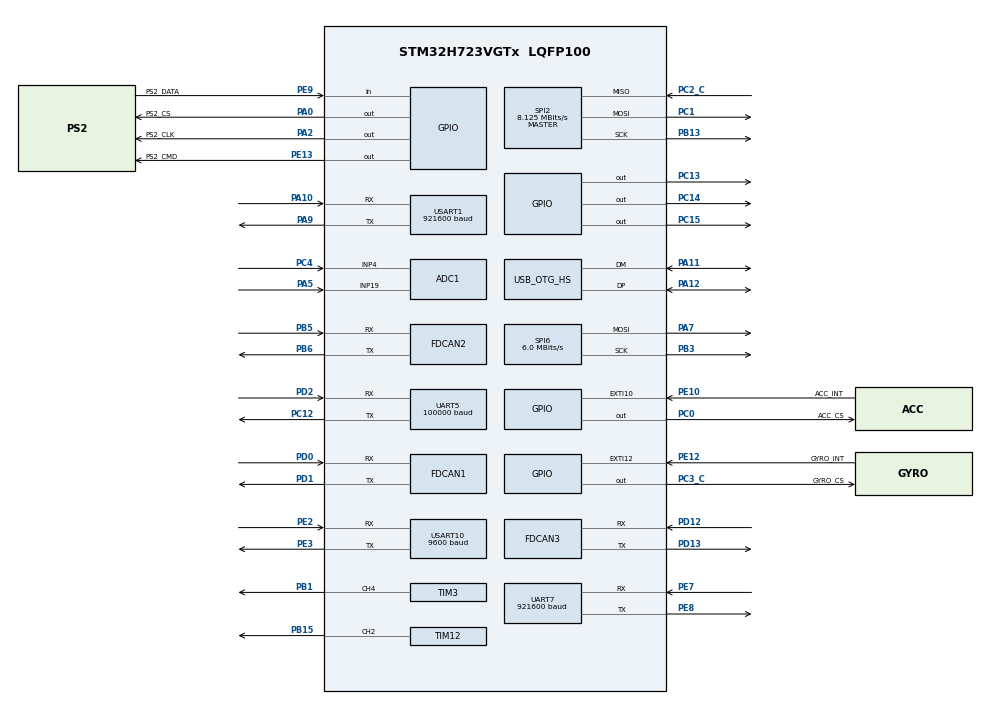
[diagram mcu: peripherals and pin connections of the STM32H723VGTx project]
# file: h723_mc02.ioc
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ADC1.Channel-0\#ChannelRegularConversion=ADC_CHANNEL_4
ADC1.NbrOfConversionFlag=1
ADC1.OffsetNumber-0\#ChannelRegularConversion=ADC_OFFSET_NONE
ADC1.OffsetSignedSaturation-0\#ChannelRegularConversion=DISABLE
ADC1.Rank-0\#ChannelRegularConversion=1
ADC1.SamplingTime-0\#ChannelRegularConversion=ADC_SAMPLETIME_1CYCLE_5
ADC1.master=1
CORTEX_M7.AccessPermission_Spec=MPU_REGION_FULL_ACCESS
CORTEX_M7.BaseAddress_Spec=0x24000000
CORTEX_M7.CPU_DCache=Enabled
CORTEX_M7.CPU_ICache=Enabled
CORTEX_M7.DisableExec_Spec=MPU_INSTRUCTION_ACCESS_ENABLE
CORTEX_M7.IsShareable_Spec=MPU_ACCESS_SHAREABLE
CORTEX_M7.MPU_Control=__NULL
CORTEX_M7.Size_Spec=MPU_REGION_SIZE_512KB
CORTEX_M7.SubRegionDisable_Spec=0x0
CORTEX_M7.TypeExtField_Spec=MPU_TEX_LEVEL1
CORTEX_M7.default_mode_Activation=0
Dma.Request0=USART1_RX
Dma.Request1=USART1_TX
Dma.Request2=UART7_RX
Dma.Request3=UART7_TX
Dma.Request4=UART5_RX
Dma.Request5=SPI2_RX
Dma.Request6=SPI2_TX
Dma.Request7=USART10_RX
Dma.Request8=TIM6_UP
Dma.SPI2_RX.5.Direction=DMA_PERIPH_TO_MEMORY
Dma.SPI2_RX.5.EventEnable=DISABLE
Dma.SPI2_RX.5.FIFOMode=DMA_FIFOMODE_DISABLE
Dma.SPI2_RX.5.Instance=DMA1_Stream0
Dma.SPI2_RX.5.MemDataAlignment=DMA_MDATAALIGN_BYTE
Dma.SPI2_RX.5.MemInc=DMA_MINC_ENABLE
Dma.SPI2_RX.5.Mode=DMA_NORMAL
Dma.SPI2_RX.5.PeriphDataAlignment=DMA_PDATAALIGN_BYTE
Dma.SPI2_RX.5.PeriphInc=DMA_PINC_DISABLE
Dma.SPI2_RX.5.Polarity=HAL_DMAMUX_REQ_GEN_RISING
Dma.SPI2_RX.5.Priority=DMA_PRIORITY_LOW
Dma.SPI2_RX.5.RequestNumber=1
Dma.SPI2_RX.5.SignalID=NONE
Dma.SPI2_RX.5.SyncEnable=DISABLE
Dma.SPI2_RX.5.SyncPolarity=HAL_DMAMUX_SYNC_NO_EVENT
Dma.SPI2_RX.5.SyncRequestNumber=1
Dma.SPI2_RX.5.SyncSignalID=NONE
Dma.SPI2_TX.6.Direction=DMA_MEMORY_TO_PERIPH
Dma.SPI2_TX.6.EventEnable=DISABLE
Dma.SPI2_TX.6.FIFOMode=DMA_FIFOMODE_DISABLE
Dma.SPI2_TX.6.Instance=DMA1_Stream1
Dma.SPI2_TX.6.MemDataAlignment=DMA_MDATAALIGN_BYTE
Dma.SPI2_TX.6.MemInc=DMA_MINC_ENABLE
Dma.SPI2_TX.6.Mode=DMA_NORMAL
Dma.SPI2_TX.6.PeriphDataAlignment=DMA_PDATAALIGN_BYTE
Dma.SPI2_TX.6.PeriphInc=DMA_PINC_DISABLE
Dma.SPI2_TX.6.Polarity=HAL_DMAMUX_REQ_GEN_RISING
Dma.SPI2_TX.6.Priority=DMA_PRIORITY_LOW
Dma.SPI2_TX.6.RequestNumber=1
Dma.SPI2_TX.6.SignalID=NONE
Dma.SPI2_TX.6.SyncEnable=DISABLE
Dma.SPI2_TX.6.SyncPolarity=HAL_DMAMUX_SYNC_NO_EVENT
Dma.SPI2_TX.6.SyncRequestNumber=1
Dma.SPI2_TX.6.SyncSignalID=NONE
Dma.TIM6_UP.8.Direction=DMA_MEMORY_TO_PERIPH
Dma.TIM6_UP.8.EventEnable=DISABLE
Dma.TIM6_UP.8.FIFOMode=DMA_FIFOMODE_DISABLE
Dma.TIM6_UP.8.Instance=DMA2_Stream6
Dma.TIM6_UP.8.MemDataAlignment=DMA_MDATAALIGN_WORD
Dma.TIM6_UP.8.MemInc=DMA_MINC_DISABLE
Dma.TIM6_UP.8.Mode=DMA_NORMAL
Dma.TIM6_UP.8.PeriphDataAlignment=DMA_PDATAALIGN_WORD
Dma.TIM6_UP.8.PeriphInc=DMA_PINC_DISABLE
Dma.TIM6_UP.8.Polarity=HAL_DMAMUX_REQ_GEN_RISING
Dma.TIM6_UP.8.Priority=DMA_PRIORITY_VERY_HIGH
Dma.TIM6_UP.8.RequestNumber=1
Dma.TIM6_UP.8.SignalID=NONE
Dma.TIM6_UP.8.SyncEnable=DISABLE
Dma.TIM6_UP.8.SyncPolarity=HAL_DMAMUX_SYNC_NO_EVENT
Dma.TIM6_UP.8.SyncRequestNumber=1
Dma.TIM6_UP.8.SyncSignalID=NONE
Dma.UART5_RX.4.Direction=DMA_PERIPH_TO_MEMORY
Dma.UART5_RX.4.EventEnable=DISABLE
Dma.UART5_RX.4.FIFOMode=DMA_FIFOMODE_DISABLE
Dma.UART5_RX.4.Instance=DMA2_Stream3
Dma.UART5_RX.4.MemDataAlignment=DMA_MDATAALIGN_BYTE
Dma.UART5_RX.4.MemInc=DMA_MINC_ENABLE
Dma.UART5_RX.4.Mode=DMA_CIRCULAR
Dma.UART5_RX.4.PeriphDataAlignment=DMA_PDATAALIGN_BYTE
Dma.UART5_RX.4.PeriphInc=DMA_PINC_DISABLE
Dma.UART5_RX.4.Polarity=HAL_DMAMUX_REQ_GEN_RISING
Dma.UART5_RX.4.Priority=DMA_PRIORITY_VERY_HIGH
Dma.UART5_RX.4.RequestNumber=1
Dma.UART5_RX.4.SignalID=NONE
Dma.UART5_RX.4.SyncEnable=DISABLE
Dma.UART5_RX.4.SyncPolarity=HAL_DMAMUX_SYNC_NO_EVENT
Dma.UART5_RX.4.SyncRequestNumber=1
Dma.UART5_RX.4.SyncSignalID=NONE
Dma.UART7_RX.2.Direction=DMA_PERIPH_TO_MEMORY
Dma.UART7_RX.2.EventEnable=DISABLE
Dma.UART7_RX.2.FIFOMode=DMA_FIFOMODE_DISABLE
Dma.UART7_RX.2.Instance=DMA1_Stream2
Dma.UART7_RX.2.MemDataAlignment=DMA_MDATAALIGN_BYTE
Dma.UART7_RX.2.MemInc=DMA_MINC_ENABLE
Dma.UART7_RX.2.Mode=DMA_NORMAL
Dma.UART7_RX.2.PeriphDataAlignment=DMA_PDATAALIGN_BYTE
Dma.UART7_RX.2.PeriphInc=DMA_PINC_DISABLE
Dma.UART7_RX.2.Polarity=HAL_DMAMUX_REQ_GEN_RISING
Dma.UART7_RX.2.Priority=DMA_PRIORITY_VERY_HIGH
Dma.UART7_RX.2.RequestNumber=1
Dma.UART7_RX.2.SignalID=NONE
Dma.UART7_RX.2.SyncEnable=DISABLE
Dma.UART7_RX.2.SyncPolarity=HAL_DMAMUX_SYNC_NO_EVENT
Dma.UART7_RX.2.SyncRequestNumber=1
Dma.UART7_RX.2.SyncSignalID=NONE
Dma.UART7_TX.3.Direction=DMA_MEMORY_TO_PERIPH
Dma.UART7_TX.3.EventEnable=DISABLE
Dma.UART7_TX.3.FIFOMode=DMA_FIFOMODE_DISABLE
Dma.UART7_TX.3.Instance=DMA1_Stream3
Dma.UART7_TX.3.MemDataAlignment=DMA_MDATAALIGN_BYTE
Dma.UART7_TX.3.MemInc=DMA_MINC_ENABLE
Dma.UART7_TX.3.Mode=DMA_NORMAL
Dma.UART7_TX.3.PeriphDataAlignment=DMA_PDATAALIGN_BYTE
Dma.UART7_TX.3.PeriphInc=DMA_PINC_DISABLE
Dma.UART7_TX.3.Polarity=HAL_DMAMUX_REQ_GEN_RISING
Dma.UART7_TX.3.Priority=DMA_PRIORITY_VERY_HIGH
Dma.UART7_TX.3.RequestNumber=1
Dma.UART7_TX.3.SignalID=NONE
Dma.UART7_TX.3.SyncEnable=DISABLE
Dma.UART7_TX.3.SyncPolarity=HAL_DMAMUX_SYNC_NO_EVENT
Dma.UART7_TX.3.SyncRequestNumber=1
Dma.UART7_TX.3.SyncSignalID=NONE
Dma.USART10_RX.7.Direction=DMA_PERIPH_TO_MEMORY
Dma.USART10_RX.7.EventEnable=DISABLE
Dma.USART10_RX.7.FIFOMode=DMA_FIFOMODE_DISABLE
Dma.USART10_RX.7.Instance=DMA1_Stream6
Dma.USART10_RX.7.MemDataAlignment=DMA_MDATAALIGN_BYTE
Dma.USART10_RX.7.MemInc=DMA_MINC_ENABLE
Dma.USART10_RX.7.Mode=DMA_NORMAL
Dma.USART10_RX.7.PeriphDataAlignment=DMA_PDATAALIGN_BYTE
Dma.USART10_RX.7.PeriphInc=DMA_PINC_DISABLE
Dma.USART10_RX.7.Polarity=HAL_DMAMUX_REQ_GEN_RISING
Dma.USART10_RX.7.Priority=DMA_PRIORITY_LOW
Dma.USART10_RX.7.RequestNumber=1
Dma.USART10_RX.7.SignalID=NONE
Dma.USART10_RX.7.SyncEnable=DISABLE
Dma.USART10_RX.7.SyncPolarity=HAL_DMAMUX_SYNC_NO_EVENT
Dma.USART10_RX.7.SyncRequestNumber=1
Dma.USART10_RX.7.SyncSignalID=NONE
Dma.USART1_RX.0.Direction=DMA_PERIPH_TO_MEMORY
Dma.USART1_RX.0.EventEnable=DISABLE
Dma.USART1_RX.0.FIFOMode=DMA_FIFOMODE_DISABLE
Dma.USART1_RX.0.Instance=DMA1_Stream4
Dma.USART1_RX.0.MemDataAlignment=DMA_MDATAALIGN_BYTE
Dma.USART1_RX.0.MemInc=DMA_MINC_ENABLE
Dma.USART1_RX.0.Mode=DMA_CIRCULAR
Dma.USART1_RX.0.PeriphDataAlignment=DMA_PDATAALIGN_BYTE
Dma.USART1_RX.0.PeriphInc=DMA_PINC_DISABLE
Dma.USART1_RX.0.Polarity=HAL_DMAMUX_REQ_GEN_RISING
Dma.USART1_RX.0.Priority=DMA_PRIORITY_VERY_HIGH
Dma.USART1_RX.0.RequestNumber=1
Dma.USART1_RX.0.SignalID=NONE
Dma.USART1_RX.0.SyncEnable=DISABLE
Dma.USART1_RX.0.SyncPolarity=HAL_DMAMUX_SYNC_NO_EVENT
Dma.USART1_RX.0.SyncRequestNumber=1
Dma.USART1_RX.0.SyncSignalID=NONE
Dma.USART1_TX.1.Direction=DMA_MEMORY_TO_PERIPH
Dma.USART1_TX.1.EventEnable=DISABLE
Dma.USART1_TX.1.FIFOMode=DMA_FIFOMODE_DISABLE
Dma.USART1_TX.1.Instance=DMA1_Stream5
Dma.USART1_TX.1.MemDataAlignment=DMA_MDATAALIGN_BYTE
Dma.USART1_TX.1.MemInc=DMA_MINC_ENABLE
Dma.USART1_TX.1.Mode=DMA_NORMAL
Dma.USART1_TX.1.PeriphDataAlignment=DMA_PDATAALIGN_BYTE
Dma.USART1_TX.1.PeriphInc=DMA_PINC_DISABLE
Dma.USART1_TX.1.Polarity=HAL_DMAMUX_REQ_GEN_RISING
Dma.USART1_TX.1.Priority=DMA_PRIORITY_VERY_HIGH
Dma.USART1_TX.1.RequestNumber=1
Dma.USART1_TX.1.SignalID=NONE
Dma.USART1_TX.1.SyncEnable=DISABLE
Dma.USART1_TX.1.SyncPolarity=HAL_DMAMUX_SYNC_NO_EVENT
Dma.USART1_TX.1.SyncRequestNumber=1
Dma.USART1_TX.1.SyncSignalID=NONE
FDCAN1.AutoRetransmission=ENABLE
FDCAN1.CalculateBaudRateNominal=1000000
FDCAN1.CalculateTimeBitNominal=1000
FDCAN1.CalculateTimeQuantumNominal=12.5
FDCAN1.DataPrescaler=1
FDCAN1.DataSyncJumpWidth=2
FDCAN1.DataTimeSeg1=13
FDCAN1.DataTimeSeg2=2
FDCAN1.ExtFiltersNbr=0
FDCAN1.FrameFormat=FDCAN_FRAME_FD_BRS
FDCAN1.NominalPrescaler=1
FDCAN1.NominalSyncJumpWidth=20
FDCAN1.NominalTimeSeg1=59
FDCAN1.NominalTimeSeg2=20
FDCAN1.ProtocolException=ENABLE
FDCAN1.RxBuffersNbr=0
FDCAN1.RxFifo0ElmtsNbr=0
FDCAN1.RxFifo1ElmtsNbr=24
FDCAN1.StdFiltersNbr=4
FDCAN1.TxBuffersNbr=0
FDCAN1.TxEventsNbr=0
FDCAN1.TxFifoQueueElmtsNbr=16
FDCAN2.AutoRetransmission=ENABLE
FDCAN2.CalculateBaudRateNominal=1000000
FDCAN2.CalculateTimeBitNominal=1000
FDCAN2.CalculateTimeQuantumNominal=250.0
FDCAN2.DataPrescaler=20
FDCAN2.DataSyncJumpWidth=1
FDCAN2.DataTimeSeg1=2
FDCAN2.DataTimeSeg2=1
FDCAN2.ExtFiltersNbr=0
FDCAN2.FrameFormat=FDCAN_FRAME_CLASSIC
FDCAN2.MessageRAMOffset=853
FDCAN2.NominalPrescaler=20
FDCAN2.NominalSyncJumpWidth=1
FDCAN2.NominalTimeSeg1=2
FDCAN2.NominalTimeSeg2=1
FDCAN2.ProtocolException=ENABLE
FDCAN2.RxFifo0ElmtsNbr=4
FDCAN2.RxFifo1ElmtsNbr=0
FDCAN2.StdFiltersNbr=1
FDCAN2.TxFifoQueueElmtsNbr=2
FDCAN3.AutoRetransmission=ENABLE
FDCAN3.CalculateBaudRateNominal=1000000
FDCAN3.CalculateTimeBitNominal=1000
FDCAN3.CalculateTimeQuantumNominal=250.0
FDCAN3.DataPrescaler=20
FDCAN3.DataSyncJumpWidth=1
FDCAN3.DataTimeSeg1=2
FDCAN3.DataTimeSeg2=1
FDCAN3.ExtFiltersNbr=0
FDCAN3.FrameFormat=FDCAN_FRAME_CLASSIC
FDCAN3.MessageRAMOffset=1706
FDCAN3.NominalPrescaler=20
FDCAN3.NominalSyncJumpWidth=1
FDCAN3.NominalTimeSeg1=2
FDCAN3.NominalTimeSeg2=1
FDCAN3.ProtocolException=ENABLE
FDCAN3.RxFifo0ElmtsNbr=4
FDCAN3.RxFifo1ElmtsNbr=0
FDCAN3.StdFiltersNbr=1
FDCAN3.TxFifoQueueElmtsNbr=2
Mcu.Family=STM32H7
Mcu.Name=STM32H723VGTx
Mcu.Package=LQFP100
NVIC.DMA1_Stream0_IRQn=true\:0\:0\:false\:false\:true\:false\:false\:true\:true
NVIC.DMA1_Stream1_IRQn=true\:0\:0\:false\:false\:true\:false\:false\:true\:true
NVIC.DMA1_Stream2_IRQn=true\:0\:0\:false\:false\:true\:false\:false\:true\:true
NVIC.DMA1_Stream3_IRQn=true\:0\:0\:false\:false\:true\:false\:false\:true\:true
NVIC.DMA1_Stream4_IRQn=true\:0\:0\:false\:false\:true\:false\:false\:true\:true
NVIC.DMA1_Stream5_IRQn=true\:0\:0\:false\:false\:true\:false\:false\:true\:true
NVIC.DMA1_Stream6_IRQn=true\:0\:0\:false\:false\:true\:true\:false\:true\:true
NVIC.DMA2_Stream3_IRQn=true\:0\:0\:false\:false\:true\:false\:false\:true\:true
NVIC.EXTI15_10_IRQn=true\:0\:0\:false\:false\:true\:false\:true\:true\:true
NVIC.FDCAN1_IT0_IRQn=true\:0\:0\:false\:false\:true\:false\:true\:true\:true
NVIC.FDCAN1_IT1_IRQn=true\:0\:0\:false\:false\:true\:false\:true\:true\:true
NVIC.FDCAN2_IT0_IRQn=true\:0\:0\:false\:false\:true\:false\:true\:true\:true
NVIC.FDCAN2_IT1_IRQn=true\:0\:0\:false\:false\:true\:false\:true\:true\:true
NVIC.FDCAN3_IT0_IRQn=true\:0\:0\:false\:false\:true\:false\:true\:true\:true
NVIC.OTG_HS_IRQn=true\:0\:0\:false\:false\:true\:false\:true\:true\:true
NVIC.PriorityGroup=NVIC_PRIORITYGROUP_4
NVIC.SPI2_IRQn=true\:0\:0\:false\:false\:true\:false\:false\:true\:true
NVIC.TIM23_IRQn=true\:15\:0\:false\:false\:true\:false\:false\:true\:true
NVIC.TimeBase=TIM23_IRQn
NVIC.TimeBaseIP=TIM23
NVIC.UART5_IRQn=true\:0\:0\:false\:false\:true\:false\:true\:true\:true
NVIC.UART7_IRQn=true\:0\:0\:false\:false\:true\:false\:true\:true\:true
NVIC.USART10_IRQn=true\:0\:0\:false\:false\:true\:false\:true\:true\:true
NVIC.USART1_IRQn=true\:0\:0\:false\:false\:true\:false\:true\:true\:true
PA0.GPIO_Label=PS2_CS
PA0.PinState=GPIO_PIN_SET
PA0.Signal=GPIO_Output
PA10.Mode=Asynchronous
PA10.Signal=USART1_RX
PA11.Mode=Device_Only_FS
PA11.Signal=USB_OTG_HS_DM
PA12.Mode=Device_Only_FS
PA12.Signal=USB_OTG_HS_DP
PA2.GPIO_Label=PS2_CLK
PA2.PinState=GPIO_PIN_SET
PA2.Signal=GPIO_Output
PA5.Signal=ADCx_INP19
PA7.Mode=TX_Only_Simplex_Unidirect_Master
PA7.Signal=SPI6_MOSI
PA9.Mode=Asynchronous
PA9.Signal=USART1_TX
PB1.Signal=S_TIM3_CH4
PB13.GPIO_Speed=GPIO_SPEED_FREQ_VERY_HIGH
PB13.Mode=Full_Duplex_Master
PB13.Signal=SPI2_SCK
PB15.Signal=S_TIM12_CH2
PB3(JTDO/TRACESWO).Mode=TX_Only_Simplex_Unidirect_Master
PB3(JTDO/TRACESWO).Signal=SPI6_SCK
PB5.Mode=FDCAN_Activate
PB5.Signal=FDCAN2_RX
PB6.Mode=FDCAN_Activate
PB6.Signal=FDCAN2_TX
PC0.GPIO_Label=ACC_CS
PC0.GPIO_Speed=GPIO_SPEED_FREQ_VERY_HIGH
PC0.PinState=GPIO_PIN_SET
PC0.Signal=GPIO_Output
PC1.GPIO_Speed=GPIO_SPEED_FREQ_VERY_HIGH
PC1.Mode=Full_Duplex_Master
PC1.Signal=SPI2_MOSI
PC12.Mode=Asynchronous
PC12.Signal=UART5_TX
PC13.PinState=GPIO_PIN_SET
PC13.Signal=GPIO_Output
PC14-OSC32_IN.PinState=GPIO_PIN_SET
PC14-OSC32_IN.Signal=GPIO_Output
PC15-OSC32_OUT.PinState=GPIO_PIN_SET
PC15-OSC32_OUT.Signal=GPIO_Output
PC2_C.GPIO_Speed=GPIO_SPEED_FREQ_VERY_HIGH
PC2_C.Mode=Full_Duplex_Master
PC2_C.Signal=SPI2_MISO
PC3_C.GPIO_Label=GYRO_CS
PC3_C.GPIO_Speed=GPIO_SPEED_FREQ_VERY_HIGH
PC3_C.PinState=GPIO_PIN_SET
PC3_C.Signal=GPIO_Output
PC4.Signal=ADCx_INP4
PD0.Mode=FDCAN_Activate
PD0.Signal=FDCAN1_RX
PD1.Mode=FDCAN_Activate
PD1.Signal=FDCAN1_TX
PD12.Mode=FDCAN_Activate
PD12.Signal=FDCAN3_RX
PD13.Mode=FDCAN_Activate
PD13.Signal=FDCAN3_TX
PD2.GPIO_Speed=GPIO_SPEED_FREQ_LOW
PD2.Mode=Asynchronous
PD2.Signal=UART5_RX
PE10.GPIO_Label=ACC_INT
PE10.Signal=GPXTI10
PE12.GPIO_Label=GYRO_INT
PE12.Signal=GPXTI12
PE13.GPIO_Label=PS2_CMD
PE13.PinState=GPIO_PIN_SET
PE13.Signal=GPIO_Output
PE2.Mode=Asynchronous
PE2.Signal=USART10_RX
PE3.Mode=Asynchronous
PE3.Signal=USART10_TX
PE7.Mode=Asynchronous
PE7.Signal=UART7_RX
PE8.Mode=Asynchronous
PE8.Signal=UART7_TX
PE9.GPIO_Label=PS2_DATA
PE9.Signal=GPIO_Input
PH0-OSC_IN.Mode=HSE-External-Oscillator
PH0-OSC_IN.Signal=RCC_OSC_IN
PH1-OSC_OUT.Mode=HSE-External-Oscillator
PH1-OSC_OUT.Signal=RCC_OSC_OUT
ProjectManager.HeapSize=0x4000
ProjectManager.StackSize=0x4500
ProjectManager.TargetToolchain=CMake
RCC.ADCFreq_Value=120000000
RCC.APB1Freq_Value=130000000
RCC.APB2Freq_Value=130000000
RCC.APB3Freq_Value=130000000
RCC.APB4Freq_Value=130000000
RCC.CortexFreq_Value=520000000
RCC.D1PPRE=RCC_APB3_DIV2
RCC.D2PPRE1=RCC_APB1_DIV2
RCC.D2PPRE2=RCC_APB2_DIV2
RCC.D3PPRE=RCC_APB4_DIV2
RCC.DIVM1=3
RCC.DIVM2=2
RCC.DIVM3=2
RCC.DIVN1=65
RCC.DIVN2=20
RCC.DIVN3=16
RCC.DIVP1=1
RCC.DIVP3=1
RCC.DIVQ1=4
RCC.DIVQ2=3
RCC.FDCANCLockSelection=RCC_FDCANCLKSOURCE_PLL2
RCC.HCLKFreq_Value=260000000
RCC.HPRE=RCC_HCLK_DIV2
RCC.HSE_VALUE=24000000
RCC.PLL2FRACN=0
RCC.PLL3FRACN=0
RCC.PLL3_VCI_Range-AdvancedSettings=RCC_PLL3VCIRANGE_3
RCC.PLLFRACN=0
RCC.PLLSourceVirtual=RCC_PLLSOURCE_HSE
RCC.SPI6CLockSelection=RCC_SPI6CLKSOURCE_HSE
RCC.SYSCLKFreq_VALUE=520000000
RCC.SYSCLKSource=RCC_SYSCLKSOURCE_PLLCLK
RCC.USBCLockSelection=RCC_USBCLKSOURCE_HSI48
RCC.USBFreq_Value=48000000
SH.ADCx_INP19.0=ADC1_INP19,IN19-Single-Ended
SH.ADCx_INP4.0=ADC1_INP4,IN4-Single-Ended
SH.S_TIM12_CH2.0=TIM12_CH2,PWM Generation2 CH2
SH.S_TIM3_CH4.0=TIM3_CH4,PWM Generation4 CH4
SPI2.BaudRatePrescaler=SPI_BAUDRATEPRESCALER_16
SPI2.CLKPhase=SPI_PHASE_2EDGE
SPI2.CLKPolarity=SPI_POLARITY_HIGH
SPI2.CalculateBaudRate=8.125 MBits/s
SPI2.DataSize=SPI_DATASIZE_8BIT
SPI2.Direction=SPI_DIRECTION_2LINES
SPI2.Mode=SPI_MODE_MASTER
SPI2.VirtualType=VM_MASTER
SPI6.BaudRatePrescaler=SPI_BAUDRATEPRESCALER_4
SPI6.CLKPhase=SPI_PHASE_2EDGE
SPI6.CalculateBaudRate=6.0 MBits/s
SPI6.DataSize=SPI_DATASIZE_8BIT
SPI6.Direction=SPI_DIRECTION_2LINES_TXONLY
SPI6.Mode=SPI_MODE_MASTER
SPI6.VirtualType=VM_MASTER
STMicroelectronics.X-CUBE-ALGOBUILD.1.4.0.LibraryCcDSPOoLibraryJjDSPOoLibrary=true
STMicroelectronics.X-CUBE-AZRTOS-H7.3.4.0.TX_DISABLE_ERROR_CHECKING=1
STMicroelectronics.X-CUBE-AZRTOS-H7.3.4.0.TX_DISABLE_REDUNDANT_CLEARING=1
STMicroelectronics.X-CUBE-AZRTOS-H7.3.4.0.TX_DISABLE_STACK_FILLING=1
STMicroelectronics.X-CUBE-AZRTOS-H7.3.4.0.TX_INLINE_THREAD_RESUME_SUSPEND=1
STMicroelectronics.X-CUBE-AZRTOS-H7.3.4.0.TX_NOT_INTERRUPTABLE=1
STMicroelectronics.X-CUBE-AZRTOS-H7.3.4.0.TX_REACTIVATE_INLINE=1
STMicroelectronics.X-CUBE-AZRTOS-H7.3.4.0.TX_TIMER_PROCESS_IN_ISR=1
STMicroelectronics.X-CUBE-AZRTOS-H7.3.4.0.TX_TIMER_TICKS_PER_SECOND=1000
STMicroelectronics.X-CUBE-AZRTOS-H7.3.4.0.ThreadXCcRTOSJjThreadXJjCore=true
STMicroelectronics.X-CUBE-AZRTOS-H7.3.4.0.USBD_CDCACM_EPINCMD_ADDR=2
STMicroelectronics.X-CUBE-AZRTOS-H7.3.4.0.USBD_PRODUCT_STRING=Doraemon
STMicroelectronics.X-CUBE-AZRTOS-H7.3.4.0.USBD_SERIAL_NUMBER=LXYPIG
STMicroelectronics.X-CUBE-AZRTOS-H7.3.4.0.USBXCcUSBJjUSBXJjCoreSystem=true
STMicroelectronics.X-CUBE-AZRTOS-H7.3.4.0.USBXCcUSBJjUSBXJjUXOoDeviceOoClassOoCDCOoACM=true
STMicroelectronics.X-CUBE-AZRTOS-H7.3.4.0.USBXCcUSBJjUSBXJjUXOoDeviceOoControllers=true
STMicroelectronics.X-CUBE-AZRTOS-H7.3.4.0.USBXCcUSBJjUSBXJjUXOoDeviceOoCoreStack=true
STMicroelectronics.X-CUBE-AZRTOS-H7.3.4.0.USBX_DEVICE_SYS_SIZE=7*1024
STMicroelectronics.X-CUBE-AZRTOS-H7.3.4.0.UX_DEVICE_APP_MEM_POOL_SIZE=12*1024
STMicroelectronics.X-CUBE-AZRTOS-H7.3.4.0.UX_DEVICE_SIDE_ONLY=1
STMicroelectronics.X-CUBE-AZRTOS-H7.3.4.0.UX_PERIODIC_RATE=1000
STMicroelectronics.X-CUBE-AZRTOS-H7.3.4.0.UX_SLAVE_REQUEST_DATA_MAX_LENGTH=512
STMicroelectronics.X-CUBE-AZRTOS-H7.3.4.0.UX_THREAD_STACK_SIZE=2048
STMicroelectronics.X-CUBE-AZRTOS-H7.3.4.0_IsAnAzureRtosMw=true
TIM12.Channel-PWM\ Generation2\ CH2=TIM_CHANNEL_2
TIM12.Period=2000-1
TIM12.Prescaler=24-1
TIM12.Pulse-PWM\ Generation2\ CH2=1000
TIM3.Channel-PWM\ Generation4\ CH4=TIM_CHANNEL_4
TIM3.Period=2000-1
TIM3.Prescaler=33-1
TIM6.Period=2500-1
TIM6.Prescaler=26000-1
UART5.BaudRate=100000
UART5.Mode=MODE_RX
UART5.StopBits=UART_STOPBITS_2
UART5.WordLength=WORDLENGTH_9B
UART7.BaudRate=921600
USART1.BaudRate=921600
USART1.VirtualMode-Asynchronous=VM_ASYNC
USART10.BaudRate=9600
USART10.VirtualMode=VM_ASYNC
USB_OTG_HS.VirtualMode-Device_Only_FS=Device_Only_FS
VP_CRC_VS_CRC.Mode=CRC_Activate
VP_MEMORYMAP_VS_MEMORYMAP.Mode=CurAppReg
VP_RCC_USB.Mode=USB_HS
VP_STMicroelectronics.X-CUBE-ALGOBUILD_VS_DSPOoLibraryJjLibrary_1.4.0_1.4.0.Mode=DSPOoLibraryJjLibrary
VP_STMicroelectronics.X-CUBE-AZRTOS-H7_VS_RTOSJjThreadX_6.4.0_3.4.0.Mode=RTOSJjThreadX
VP_STMicroelectronics.X-CUBE-AZRTOS-H7_VS_USBJjUSBX_6.4.0_3.4.0.Mode=USBJjUSBX
VP_SYS_VS_tim23.Mode=TIM23
VP_TIM6_VS_ClockSourceINT.Mode=Enable_Timer
VP_TIM6_VS_OPM.Mode=OPM_bit
board=custom
TIM7.Period=65535
TIM7.Prescaler=260-1
VP_TIM7_VS_ClockSourceINT.Mode=Enable_Timer
VP_TIM7_VS_OPM.Mode=OPM_bit
NVIC.TIM7_IRQn=true\:14\:0\:true\:false\:true\:false\:true\:true\:true

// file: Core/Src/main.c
/* USER CODE BEGIN Header */
/**
  ******************************************************************************
  * @file           : main.c
  * @brief          : Main program body
  ******************************************************************************
  * @attention
  *
  * Copyright (c) 2026 STMicroelectronics.
  * All rights reserved.
  *
  * This software is licensed under terms that can be found in the LICENSE file
  * in the root directory of this software component.
  * If no LICENSE file comes with this software, it is provided AS-IS.
  *
  ******************************************************************************
  */
/* USER CODE END Header */
#include "app_threadx.h"
#include "main.h"
#include "adc.h"
#include "crc.h"
#include "dma.h"
#include "fdcan.h"
#include "spi.h"
#include "tim.h"
#include "usart.h"
#include "usb_otg.h"
#include "gpio.h"

/* USER CODE BEGIN Includes */
#include "bsp_timer.h"

/* USER CODE END Includes */

void SystemClock_Config(void);
void PeriphCommonClock_Config(void);

int main(void)
{

  /* Enable the CPU Cache */

  /* Enable I-Cache---------------------------------------------------------*/
  SCB_EnableICache();

  /* Enable D-Cache---------------------------------------------------------*/
  SCB_EnableDCache();

  /* MCU Configuration--------------------------------------------------------*/

  /* Reset of all peripherals, Initializes the Flash interface and the Systick. */
  HAL_Init();

  /* Configure the system clock */
  SystemClock_Config();

  /* Configure the peripherals common clocks */
  PeriphCommonClock_Config();

  /* Initialize all configured peripherals */
  MX_GPIO_Init();
  MX_DMA_Init();
  MX_FDCAN1_Init();
  MX_FDCAN2_Init();
  MX_FDCAN3_Init();
  MX_USART1_UART_Init();
  MX_ADC1_Init();
  MX_SPI6_Init();
  MX_TIM12_Init();
  MX_UART5_Init();
  MX_UART7_Init();
  MX_SPI2_Init();
  MX_TIM3_Init();
  MX_CRC_Init();
  MX_USB_OTG_HS_PCD_Init();
  MX_USART10_UART_Init();
  MX_TIM6_Init();
  MX_TIM7_Init();

  MX_ThreadX_Init();

  /* We should never get here as control is now taken by the scheduler */

  /* Infinite loop */
  while (1)
  {

  }
}

void SystemClock_Config(void)
{
  RCC_OscInitTypeDef RCC_OscInitStruct = {0};
  RCC_ClkInitTypeDef RCC_ClkInitStruct = {0};
  RCC_CRSInitTypeDef RCC_CRSInitStruct = {0};

  /** Supply configuration update enable
  */
  HAL_PWREx_ConfigSupply(PWR_LDO_SUPPLY);

  /** Configure the main internal regulator output voltage
  */
  __HAL_PWR_VOLTAGESCALING_CONFIG(PWR_REGULATOR_VOLTAGE_SCALE0);

  while(!__HAL_PWR_GET_FLAG(PWR_FLAG_VOSRDY)) {}

  /** Initializes the RCC Oscillators according to the specified parameters
  * in the RCC_OscInitTypeDef structure.
  */
  RCC_OscInitStruct.OscillatorType = RCC_OSCILLATORTYPE_HSI48|RCC_OSCILLATORTYPE_HSE;
  RCC_OscInitStruct.HSEState = RCC_HSE_ON;
  RCC_OscInitStruct.HSI48State = RCC_HSI48_ON;
  RCC_OscInitStruct.PLL.PLLState = RCC_PLL_ON;
  RCC_OscInitStruct.PLL.PLLSource = RCC_PLLSOURCE_HSE;
  RCC_OscInitStruct.PLL.PLLM = 3;
  RCC_OscInitStruct.PLL.PLLN = 65;
  RCC_OscInitStruct.PLL.PLLP = 1;
  RCC_OscInitStruct.PLL.PLLQ = 4;
  RCC_OscInitStruct.PLL.PLLR = 2;
  RCC_OscInitStruct.PLL.PLLRGE = RCC_PLL1VCIRANGE_3;
  RCC_OscInitStruct.PLL.PLLVCOSEL = RCC_PLL1VCOWIDE;
  RCC_OscInitStruct.PLL.PLLFRACN = 0;
  if (HAL_RCC_OscConfig(&RCC_OscInitStruct) != HAL_OK)
  {
    Error_Handler();
  }

  /** Initializes the CPU, AHB and APB buses clocks
  */
  RCC_ClkInitStruct.ClockType = RCC_CLOCKTYPE_HCLK|RCC_CLOCKTYPE_SYSCLK
                              |RCC_CLOCKTYPE_PCLK1|RCC_CLOCKTYPE_PCLK2
                              |RCC_CLOCKTYPE_D3PCLK1|RCC_CLOCKTYPE_D1PCLK1;
  RCC_ClkInitStruct.SYSCLKSource = RCC_SYSCLKSOURCE_PLLCLK;
  RCC_ClkInitStruct.SYSCLKDivider = RCC_SYSCLK_DIV1;
  RCC_ClkInitStruct.AHBCLKDivider = RCC_HCLK_DIV2;
  RCC_ClkInitStruct.APB3CLKDivider = RCC_APB3_DIV2;
  RCC_ClkInitStruct.APB1CLKDivider = RCC_APB1_DIV2;
  RCC_ClkInitStruct.APB2CLKDivider = RCC_APB2_DIV2;
  RCC_ClkInitStruct.APB4CLKDivider = RCC_APB4_DIV2;

  if (HAL_RCC_ClockConfig(&RCC_ClkInitStruct, FLASH_LATENCY_3) != HAL_OK)
  {
    Error_Handler();
  }

  /** Enable the SYSCFG APB clock
  */
  __HAL_RCC_CRS_CLK_ENABLE();

  /** Configures CRS
  */
  RCC_CRSInitStruct.Prescaler = RCC_CRS_SYNC_DIV1;
  RCC_CRSInitStruct.Source = RCC_CRS_SYNC_SOURCE_USB2;
  RCC_CRSInitStruct.Polarity = RCC_CRS_SYNC_POLARITY_RISING;
  RCC_CRSInitStruct.ReloadValue = __HAL_RCC_CRS_RELOADVALUE_CALCULATE(48000000,1000);
  RCC_CRSInitStruct.ErrorLimitValue = 34;
  RCC_CRSInitStruct.HSI48CalibrationValue = 32;

  HAL_RCCEx_CRSConfig(&RCC_CRSInitStruct);
}

void PeriphCommonClock_Config(void)
{
  RCC_PeriphCLKInitTypeDef PeriphClkInitStruct = {0};

  /** Initializes the peripherals clock
  */
  PeriphClkInitStruct.PeriphClockSelection = RCC_PERIPHCLK_ADC|RCC_PERIPHCLK_FDCAN;
  PeriphClkInitStruct.PLL2.PLL2M = 2;
  PeriphClkInitStruct.PLL2.PLL2N = 20;
  PeriphClkInitStruct.PLL2.PLL2P = 2;
  PeriphClkInitStruct.PLL2.PLL2Q = 3;
  PeriphClkInitStruct.PLL2.PLL2R = 2;
  PeriphClkInitStruct.PLL2.PLL2RGE = RCC_PLL2VCIRANGE_3;
  PeriphClkInitStruct.PLL2.PLL2VCOSEL = RCC_PLL2VCOWIDE;
  PeriphClkInitStruct.PLL2.PLL2FRACN = 0;
  PeriphClkInitStruct.FdcanClockSelection = RCC_FDCANCLKSOURCE_PLL2;
  PeriphClkInitStruct.AdcClockSelection = RCC_ADCCLKSOURCE_PLL2;
  if (HAL_RCCEx_PeriphCLKConfig(&PeriphClkInitStruct) != HAL_OK)
  {
    Error_Handler();
  }
}

void HAL_TIM_PeriodElapsedCallback(TIM_HandleTypeDef *htim)
{
  if (htim->Instance == TIM23)
  {
    HAL_IncTick();
  }
  /* USER CODE BEGIN Callback 1 */
  bsp_timer_dispatch(htim);

  /* USER CODE END Callback 1 */
}

void Error_Handler(void)
{
  __disable_irq();
  while (1)
  {
  }
}
